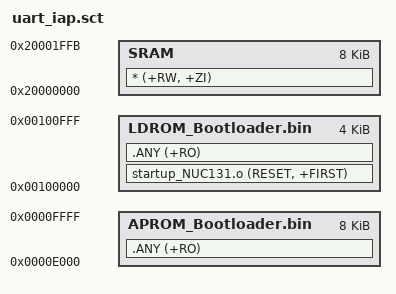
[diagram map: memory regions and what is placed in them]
LOAD_ROM_1  0x100000 0x1000
{
	LDROM_Bootloader.bin  0x100000 0x1000
	{
		startup_NUC131.o (RESET, +FIRST)
        .ANY (+RO)
	}
	
	SRAM  0x20000000 0x1FFC
	{
		* (+RW, +ZI)
	}
}

LOAD_ROM_2  0xE000 0x2000
{
	APROM_Bootloader.bin  0xE000 0x2000
	{
        .ANY (+RO)
	}
}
